# BL808 register map
Vendor: Bouffalo Lab; File version: 0.1
Registers are 32-bit, read-write, reset 0x0 unless marked. A register's access mark holds for its fields unless they carry their own. Offsets are from the block's base; [hi:lo] are bit positions; {n}, {i} and the like mark numbered series.

## EF_DATA
Base 0x20056000
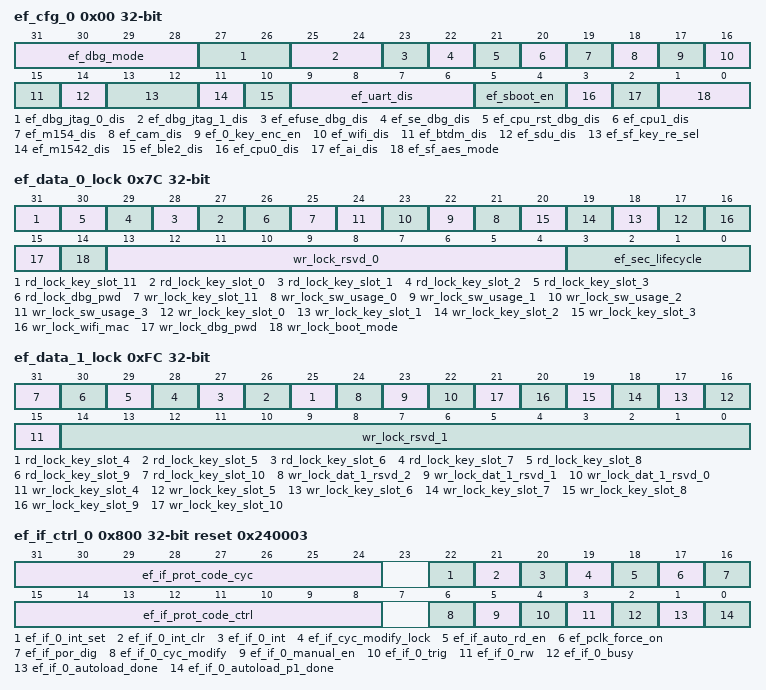
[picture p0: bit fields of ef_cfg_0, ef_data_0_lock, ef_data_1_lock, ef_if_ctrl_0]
0x00 ef_cfg_0
  [31:28] ef_dbg_mode, [27:26] ef_dbg_jtag_0_dis, [25:24] ef_dbg_jtag_1_dis, [23] ef_efuse_dbg_dis, [22] ef_se_dbg_dis, [21] ef_cpu_rst_dbg_dis, [20] ef_cpu1_dis, [19] ef_m154_dis, [18] ef_cam_dis, [17] ef_0_key_enc_en, [16] ef_wifi_dis, [15] ef_btdm_dis, [14] ef_sdu_dis, [13:12] ef_sf_key_re_sel, [11] ef_m1542_dis, [10] ef_ble2_dis, [9:6] ef_uart_dis, [5:4] ef_sboot_en, [3] ef_cpu0_dis, [2] ef_ai_dis, [1:0] ef_sf_aes_mode
0x04 ef_dbg_pwd_low
0x08 ef_dbg_pwd_high
0x0C ef_dbg_pwd2_low
0x10 ef_dbg_pwd2_high
0x14 ef_wifi_mac_low
0x18 ef_wifi_mac_high
{0x1C+0x10*i} ef_key_slot_{i}_w0 (i=0..3)
{0x20+0x10*i} ef_key_slot_{i}_w1 (i=0..3)
{0x24+0x10*i} ef_key_slot_{i}_w2 (i=0..3)
{0x28+0x10*i} ef_key_slot_{i}_w3 (i=0..3)
{0x5C+4i} ef_sw_usage_{i} (i=0..3)
0x6C ef_key_slot_11_w0
0x70 ef_key_slot_11_w1
0x74 ef_key_slot_11_w2
0x78 ef_key_slot_11_w3
0x7C ef_data_0_lock
  [31] rd_lock_key_slot_11, [n+27] rd_lock_key_slot_{n} (n=0..3), [26] rd_lock_dbg_pwd, [25] wr_lock_key_slot_11, [n+21] wr_lock_sw_usage_{n} (n=0..3), [n+17] wr_lock_key_slot_{n} (n=0..3), [16] wr_lock_wifi_mac, [15] wr_lock_dbg_pwd, [14] wr_lock_boot_mode, [13:4] wr_lock_rsvd_0, [3:0] ef_sec_lifecycle
{0x40+0x10*i} ef_key_slot_{i}_w0 (i=4..10)
{0x44+0x10*i} ef_key_slot_{i}_w1 (i=4..10)
{0x48+0x10*i} ef_key_slot_{i}_w2 (i=4..10)
{0x4C+0x10*i} ef_key_slot_{i}_w3 (i=4..10)
{0xF0+4i} ef_dat_1_rsvd_{i} (i=0..2)
0xFC ef_data_1_lock
  [n+21] rd_lock_key_slot_{n} (n=4..10), [24] wr_lock_dat_1_rsvd_2, [23] wr_lock_dat_1_rsvd_1, [22] wr_lock_dat_1_rsvd_0, [n+11] wr_lock_key_slot_{n} (n=4..10), [14:0] wr_lock_rsvd_1
0x800 ef_if_ctrl_0 reset 0x240003
  [31:24] ef_if_prot_code_cyc, [22] ef_if_0_int_set, [21] ef_if_0_int_clr, [20] ef_if_0_int ro, [19] ef_if_cyc_modify_lock, [18] ef_if_auto_rd_en, [17] ef_pclk_force_on, [16] ef_if_por_dig, [15:8] ef_if_prot_code_ctrl, [6] ef_if_0_cyc_modify, [5] ef_if_0_manual_en, [4] ef_if_0_trig, [3] ef_if_0_rw, [2] ef_if_0_busy ro, [1] ef_if_0_autoload_done ro, [0] ef_if_0_autoload_p1_done ro
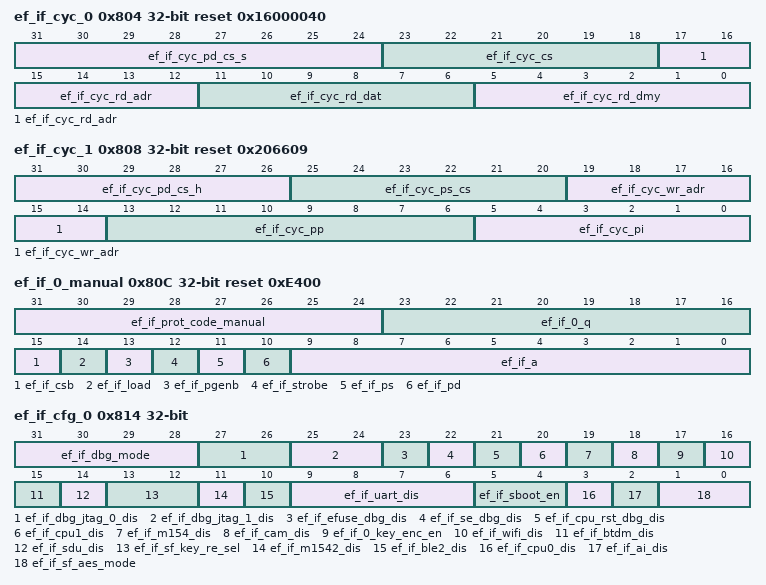
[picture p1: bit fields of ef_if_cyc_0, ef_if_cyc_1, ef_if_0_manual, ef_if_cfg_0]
0x804 ef_if_cyc_0 reset 0x16000040
  [31:24] ef_if_cyc_pd_cs_s, [23:18] ef_if_cyc_cs, [17:12] ef_if_cyc_rd_adr, [11:6] ef_if_cyc_rd_dat, [5:0] ef_if_cyc_rd_dmy
0x808 ef_if_cyc_1 reset 0x206609
  [31:26] ef_if_cyc_pd_cs_h, [25:20] ef_if_cyc_ps_cs, [19:14] ef_if_cyc_wr_adr, [13:6] ef_if_cyc_pp, [5:0] ef_if_cyc_pi
0x80C ef_if_0_manual reset 0xE400
  [31:24] ef_if_prot_code_manual, [23:16] ef_if_0_q ro, [15] ef_if_csb, [14] ef_if_load, [13] ef_if_pgenb, [12] ef_if_strobe, [11] ef_if_ps, [10] ef_if_pd, [9:0] ef_if_a
0x810 ef_if_0_status reset 0xE400
  [31:0] ef_if_0_status ro
0x814 ef_if_cfg_0
  [31:28] ef_if_dbg_mode ro, [27:26] ef_if_dbg_jtag_0_dis ro, [25:24] ef_if_dbg_jtag_1_dis ro, [23] ef_if_efuse_dbg_dis ro, [22] ef_if_se_dbg_dis ro, [21] ef_if_cpu_rst_dbg_dis ro, [20] ef_if_cpu1_dis ro, [19] ef_if_m154_dis ro, [18] ef_if_cam_dis ro, [17] ef_if_0_key_enc_en ro, [16] ef_if_wifi_dis ro, [15] ef_if_btdm_dis ro, [14] ef_if_sdu_dis ro, [13:12] ef_if_sf_key_re_sel ro, [11] ef_if_m1542_dis ro, [10] ef_if_ble2_dis ro, [9:6] ef_if_uart_dis ro, [5:4] ef_if_sboot_en ro, [3] ef_if_cpu0_dis ro, [2] ef_if_ai_dis ro, [1:0] ef_if_sf_aes_mode ro
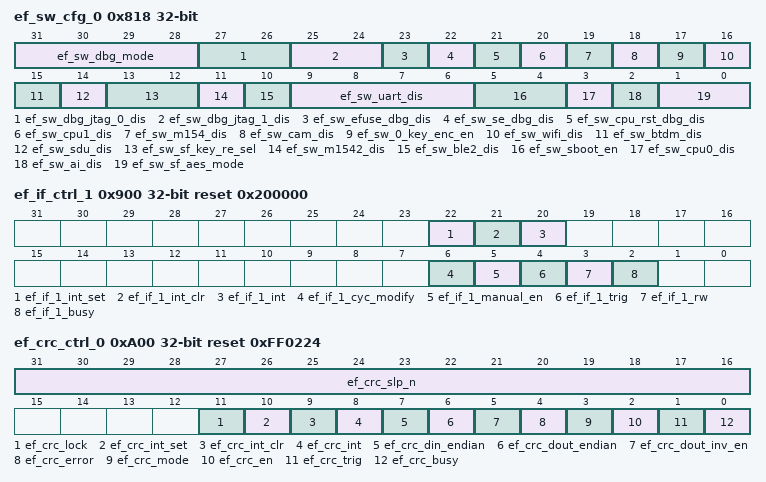
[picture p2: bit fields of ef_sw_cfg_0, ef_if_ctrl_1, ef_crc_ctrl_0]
0x818 ef_sw_cfg_0
  [31:28] ef_sw_dbg_mode, [27:26] ef_sw_dbg_jtag_0_dis, [25:24] ef_sw_dbg_jtag_1_dis, [23] ef_sw_efuse_dbg_dis, [22] ef_sw_se_dbg_dis, [21] ef_sw_cpu_rst_dbg_dis, [20] ef_sw_cpu1_dis, [19] ef_sw_m154_dis, [18] ef_sw_cam_dis, [17] ef_sw_0_key_enc_en, [16] ef_sw_wifi_dis, [15] ef_sw_btdm_dis, [14] ef_sw_sdu_dis, [13:12] ef_sw_sf_key_re_sel, [11] ef_sw_m1542_dis, [10] ef_sw_ble2_dis, [9:6] ef_sw_uart_dis, [5:4] ef_sw_sboot_en, [3] ef_sw_cpu0_dis, [2] ef_sw_ai_dis, [1:0] ef_sw_sf_aes_mode
0x81C ef_reserved reset 0xFFFF
0x820 ef_if_sw_usage_0
  [31:0] ef_if_sw_usage_0 ro
0x824 ef_if_sw_usage_1
  [31:0] ef_if_sw_usage_1 ro
0x900 ef_if_ctrl_1 reset 0x200000
  [22] ef_if_1_int_set, [21] ef_if_1_int_clr, [20] ef_if_1_int ro, [6] ef_if_1_cyc_modify, [5] ef_if_1_manual_en, [4] ef_if_1_trig, [3] ef_if_1_rw, [2] ef_if_1_busy ro
0x904 ef_if_1_manual
  [23:16] ef_if_1_q ro
0x908 ef_if_1_status reset 0xE400
  [31:0] ef_if_1_status ro
0x910 ef_if_ctrl_2
0x914 ef_if_2_manual
0x918 ef_if_2_status
0xA00 ef_crc_ctrl_0 reset 0xFF0224
  [31:16] ef_crc_slp_n, [11] ef_crc_lock, [10] ef_crc_int_set, [9] ef_crc_int_clr, [8] ef_crc_int ro, [7] ef_crc_din_endian, [6] ef_crc_dout_endian, [5] ef_crc_dout_inv_en, [4] ef_crc_error ro, [3] ef_crc_mode, [2] ef_crc_en, [1] ef_crc_trig, [0] ef_crc_busy ro
{0xA00+4i} ef_crc_ctrl_{i} (i=1..5)
